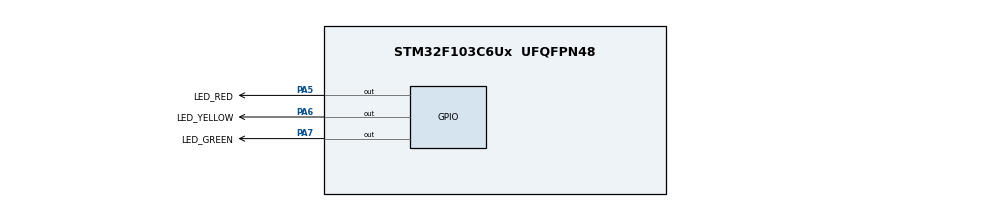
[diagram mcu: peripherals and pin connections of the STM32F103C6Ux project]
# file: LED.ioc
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Mcu.Family=STM32F1
Mcu.Name=STM32F103C6Ux
Mcu.Package=UFQFPN48
NVIC.PriorityGroup=NVIC_PRIORITYGROUP_4
PA5.GPIO_Label=LED_RED
PA5.Signal=GPIO_Output
PA6.GPIO_Label=LED_YELLOW
PA6.Signal=GPIO_Output
PA7.GPIO_Label=LED_GREEN
PA7.Signal=GPIO_Output
ProjectManager.HeapSize=0x200
ProjectManager.StackSize=0x400
ProjectManager.TargetToolchain=STM32CubeIDE
RCC.APB1Freq_Value=8000000
RCC.APB2Freq_Value=8000000
VP_SYS_VS_ND.Mode=No_Debug
board=custom

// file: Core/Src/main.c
/* USER CODE BEGIN Header */
/**
  ******************************************************************************
  * @file           : main.c
  * @brief          : Traffic Light Simulation (Active-Low)
  ******************************************************************************
  */
/* USER CODE END Header */

#include "main.h"

void SystemClock_Config(void);
static void MX_GPIO_Init(void);
/* USER CODE BEGIN PFP */
void ex2(void);
/* USER CODE END PFP */

/* Private user code --------------------------------------------------------- */
/* USER CODE BEGIN 0 */

void ex1(void) {
    // State 1: RED ON, YELLOW OFF
    HAL_GPIO_WritePin(GPIOA, LED_RED_Pin, GPIO_PIN_RESET);
    HAL_GPIO_WritePin(GPIOA, LED_YELLOW_Pin, GPIO_PIN_SET);
    HAL_Delay(2000);

    // State 2: RED OFF, YELLOW ON
    HAL_GPIO_WritePin(GPIOA, LED_RED_Pin, GPIO_PIN_SET);
    HAL_GPIO_WritePin(GPIOA, LED_YELLOW_Pin, GPIO_PIN_RESET);
    HAL_Delay(2000);
}
void ex2(void) {
    // Phase 1: RED Light ON (5 Seconds)
    // Active-Low: RESET = ON, SET = OFF
    HAL_GPIO_WritePin(GPIOA, LED_RED_Pin, GPIO_PIN_RESET);
    HAL_GPIO_WritePin(GPIOA, LED_YELLOW_Pin, GPIO_PIN_SET);
    HAL_GPIO_WritePin(GPIOA, LED_GREEN_Pin, GPIO_PIN_SET);
    HAL_Delay(5000);

    // Phase 2: GREEN Light ON (3 Seconds)
    HAL_GPIO_WritePin(GPIOA, LED_RED_Pin, GPIO_PIN_SET);
    HAL_GPIO_WritePin(GPIOA, LED_YELLOW_Pin, GPIO_PIN_SET);
    HAL_GPIO_WritePin(GPIOA, LED_GREEN_Pin, GPIO_PIN_RESET);
    HAL_Delay(3000);

    // Phase 3: YELLOW Light ON (2 Seconds)
    HAL_GPIO_WritePin(GPIOA, LED_RED_Pin, GPIO_PIN_SET);
    HAL_GPIO_WritePin(GPIOA, LED_YELLOW_Pin, GPIO_PIN_RESET);
    HAL_GPIO_WritePin(GPIOA, LED_GREEN_Pin, GPIO_PIN_SET);
    HAL_Delay(2000);
}
/* USER CODE END 0 */

int main(void)
{
  HAL_Init();
  SystemClock_Config();
  MX_GPIO_Init();

  /* USER CODE BEGIN 2 */
  // Initial State: Turn all LEDs OFF (Active-Low: drive HIGH)
  HAL_GPIO_WritePin(GPIOA, LED_RED_Pin | LED_YELLOW_Pin | LED_GREEN_Pin, GPIO_PIN_SET);
  /* USER CODE END 2 */

  /* Infinite loop */
  while (1)
  {

    /* USER CODE BEGIN 3 */
    ex1();
  }
  /* USER CODE END 3 */
}

void SystemClock_Config(void)
{
  RCC_OscInitTypeDef RCC_OscInitStruct = {0};
  RCC_ClkInitTypeDef RCC_ClkInitStruct = {0};

  RCC_OscInitStruct.OscillatorType = RCC_OSCILLATORTYPE_HSI;
  RCC_OscInitStruct.HSIState = RCC_HSI_ON;
  RCC_OscInitStruct.HSICalibrationValue = RCC_HSICALIBRATION_DEFAULT;
  RCC_OscInitStruct.PLL.PLLState = RCC_PLL_NONE;
  if (HAL_RCC_OscConfig(&RCC_OscInitStruct) != HAL_OK)
  {
    Error_Handler();
  }

  RCC_ClkInitStruct.ClockType = RCC_CLOCKTYPE_HCLK|RCC_CLOCKTYPE_SYSCLK
                              |RCC_CLOCKTYPE_PCLK1|RCC_CLOCKTYPE_PCLK2;
  RCC_ClkInitStruct.SYSCLKSource = RCC_SYSCLKSOURCE_HSI;
  RCC_ClkInitStruct.AHBCLKDivider = RCC_SYSCLK_DIV1;
  RCC_ClkInitStruct.APB1CLKDivider = RCC_HCLK_DIV1;
  RCC_ClkInitStruct.APB2CLKDivider = RCC_HCLK_DIV1;

  if (HAL_RCC_ClockConfig(&RCC_ClkInitStruct, FLASH_LATENCY_0) != HAL_OK)
  {
    Error_Handler();
  }
}

static void MX_GPIO_Init(void)
{
  GPIO_InitTypeDef GPIO_InitStruct = {0};

  /* GPIO Ports Clock Enable */
  __HAL_RCC_GPIOA_CLK_ENABLE();

  /* Configure initial Output Level to SET (OFF for Active-Low) */
  HAL_GPIO_WritePin(GPIOA, LED_RED_Pin|LED_YELLOW_Pin|LED_GREEN_Pin, GPIO_PIN_SET);

  /* Configure GPIO pins */
  GPIO_InitStruct.Pin = LED_RED_Pin|LED_YELLOW_Pin|LED_GREEN_Pin;
  GPIO_InitStruct.Mode = GPIO_MODE_OUTPUT_PP;
  GPIO_InitStruct.Pull = GPIO_NOPULL;
  GPIO_InitStruct.Speed = GPIO_SPEED_FREQ_LOW;
  HAL_GPIO_Init(GPIOA, &GPIO_InitStruct);
}

void Error_Handler(void)
{
  __disable_irq();
  while (1)
  {
  }
}
